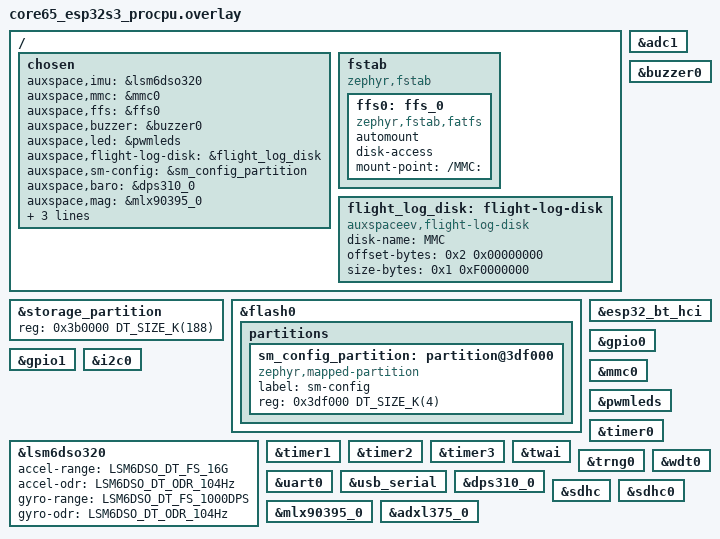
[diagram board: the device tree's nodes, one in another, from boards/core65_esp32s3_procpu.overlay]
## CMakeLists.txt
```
#-------------------------------------------------------------------------------
# Sensor Board prototype
#
# Copyright (c) 2025-2026 Auxspace e.V.
# SPDX-License-Identifier: Apache-2.0

cmake_minimum_required(VERSION 3.20.0)

# TODO: Exclude zephyr from SCA since it produces false positives
# set(ZEPHYR_SCA_VARIANT gcc)

# Make application-local snippets (e.g. ./snippets/sim) discoverable by
# `west build -S <name>` and twister's SNIPPET= extra_args.
list(APPEND SNIPPET_ROOT ${CMAKE_CURRENT_SOURCE_DIR})

find_package(Zephyr REQUIRED HINTS $ENV{ZEPHYR_BASE})

# The "app" library target below is created by find_package(Zephyr) (see
# zephyr/cmake/modules/kernel.cmake), independently of the project name.
project(sensor_board LANGUAGES C CXX)

target_sources(app PRIVATE
	src/main.c
	src/data.c
	)
```

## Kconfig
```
# Copyright (c) 2025-2026 Auxspace e.V.
# SPDX-License-Identifier: Apache-2.0
#
# This file is the application Kconfig entry point. All application Kconfig
# options can be defined here or included via other application Kconfig files.
# You can browse these options using the west targets menuconfig (terminal) or
# guiconfig (GUI).

menu "Zephyr"

source "Kconfig.zephyr"

endmenu

module = SENSOR_BOARD
module-str = SENSOR_BOARD
source "subsys/logging/Kconfig.template.log_config"

# The simulated sample sources themselves live with the sensors they stand
# in for; see AURORA_FAKE_SENSORS in aurora/lib/sensor/Kconfig.

config AURORA_SIM_AUTOTEST
	bool "Automated simulation test (CI mode)"
	depends on IMU && BARO
	depends on AURORA_STATE_MACHINE && SHELL
	select AURORA_FAKE_SENSORS
	select ASSERT
	help
	  Enables the full automated flight simulation for CI. Pulls in the
	  simulated sensors and assertion support, then has the state machine
	  thread launch the flight as soon as attitude calibration completes.
	  Exits with code 0 on SM_LANDED, code 1 on SM_ERROR or after
	  AURORA_SIM_AUTOLAUNCH_TIMEOUT_MS. Run ./zephyr.exe and check the
	  process exit code.

config AURORA_SIM_AUTOLAUNCH_TIMEOUT_MS
	int "Autolaunch watchdog timeout (ms)"
	depends on AURORA_SIM_AUTOTEST
	default 120000
	help
	  Maximum time in milliseconds to wait for SM_LANDED after launching
	  the flight. Exits with code 1 if this deadline is exceeded.

config SENSOR_BOARD_STATUS_INTERVAL_MS
	int "Telemetry status heartbeat interval (ms)"
	depends on AURORA_TELEMETRY && AURORA_STATE_MACHINE
	default 1000
	range 0 60000
	help
	  Period of the STATUS telemetry frame sent while the vehicle is
	  not in flight (pad, error hold, landed). It carries the flight
	  state and sensor/calibration/log health, and unlike SM updates
	  it does not wait for both sensors to report - so the ground
	  station hears from a board whose IMU or barometer is down.
	  Suppressed in flight, where it would compete with SM updates
	  for airtime. 0 disables it.

config SENSOR_BOARD_TELEMETRY_FOLLOW_SM
	bool "Send SM updates only when the state machine advances"
	depends on AURORA_TELEMETRY && AURORA_STATE_MACHINE
	default y
	help
	  When enabled, an SM_UPDATE frame goes out on every state machine
	  step, which only happens once both the IMU and the barometer have
	  delivered a sample.  Without a working barometer no SM_UPDATE is
	  ever sent; only the STATUS heartbeat reaches the ground.

	  When disabled, SM_UPDATE frames are sent from the flight loop
	  every SENSOR_BOARD_TELEMETRY_INTERVAL_MS, independent of the
	  state machine, carrying whatever the sensors last delivered.
	  Use this to keep the downlink alive when the state machine cannot
	  advance, e.g. flying without a barometer.  Altitude then stays 0;
	  acceleration, vertical acceleration and orientation come from the
	  IMU.  Backend rate limits (*_MIN_INTERVAL_MS) still apply.

config SENSOR_BOARD_TELEMETRY_INTERVAL_MS
	int "SM update interval when not following the state machine (ms)"
	depends on AURORA_TELEMETRY && AURORA_STATE_MACHINE
	depends on !SENSOR_BOARD_TELEMETRY_FOLLOW_SM
	default 100
	range 10 60000
	help
	  Period of the SM_UPDATE frames sent while
	  SENSOR_BOARD_TELEMETRY_FOLLOW_SM is disabled.
```

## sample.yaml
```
# Copyright (c) 2026 Auxspace e.V.
# SPDX-License-Identifier: Apache-2.0
#
# This file is provided so that the application can be compiled using Twister,
# the Zephyr testing tool. In this file, multiple combinations can be specified,
# so that you can easily test all of them locally or in CI.
sample:
  description: Sensor Board Application
  name: Sensor Board
common:
  build_only: true
  modules:
    - fatfs
tests:
  app.native_sim.replay:
    build_only: false
    timeout: 180
    harness: console
    harness_config:
      type: one_line
      regex:
        - "simulation complete"
    extra_overlay_confs:
      - boards/native_sim.conf
    extra_dtc_overlay_files:
      - boards/native_sim.overlay
    extra_configs:
      - CONFIG_AURORA_SIM_AUTOTEST=y
      - CONFIG_AURORA_FAKE_SENSORS_REPLAY=y
    platform_allow:
      - native_sim/native/64
    integration_platforms:
      - native_sim/native/64
  app.default.sysbuild:
    sysbuild: true
    platform_allow:
      - sensor_board_v2/rp2040
      - micrometer@2/esp32s3/procpu
      - core65@1/esp32s3/procpu
    integration_platforms:
      - sensor_board_v2/rp2040
      - micrometer@2/esp32s3/procpu
      - core65@1/esp32s3/procpu
  app.bench:
    extra_args: SNIPPET="sim;nodisk"
    platform_allow:
      - rpi_pico/rp2040/w
      - sensor_board_v2/rp2040
    integration_platforms:
      - rpi_pico/rp2040/w
      - sensor_board_v2/rp2040
  app.debug.sysbuild:
    sysbuild: true
    extra_overlay_confs:
      - debug.conf
    platform_allow:
      - sensor_board_v2/rp2040
      - micrometer@2/esp32s3/procpu
      - core65@1/esp32s3/procpu
    integration_platforms:
      - sensor_board_v2/rp2040
      - micrometer@2/esp32s3/procpu
      - core65@1/esp32s3/procpu
```

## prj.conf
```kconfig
# Copyright (c) 2026 Auxspace e.V.
# SPDX-License-Identifier: Apache-2.0
#
# common options, which apply to all boards (will be duplicated in board configs)

# Console and Shell
CONFIG_SHELL=y
CONFIG_SENSOR_SHELL=y

# Boot banner
CONFIG_BOOT_BANNER_STRING="Booting AURORA"

# Logging
CONFIG_LOG=y
CONFIG_LOG_FLUSH_SLEEP_US=1000
CONFIG_LOG_DEFAULT_LEVEL=3
CONFIG_LOG_TIMESTAMP_USE_REALTIME=y
CONFIG_LOG_SPEED=y
CONFIG_LOG_THREAD_ID_PREFIX=y
CONFIG_LOG_INFO_COLOR_GREEN=y
CONFIG_LOG_DBG_COLOR_BLUE=y
CONFIG_LOG_OUTPUT_FORMAT_TIME_TIMESTAMP=y
# CONFIG_LOG_BACKEND_FS_APPEND_TO_NEWEST_FILE is not set
# CONFIG_LOG_MEM_UTILIZATION is not set
CONFIG_LOG_CMDS=y
CONFIG_LOG_RATELIMIT_INTERVAL_MS=500

# State machine
CONFIG_AURORA_STATE_MACHINE=y
CONFIG_AURORA_STATE_MACHINE_SHELL=y

# The flight thread reads its samples directly; zbus is left for the observers
# that only listen in, such as the pad link.
CONFIG_ZBUS=y
CONFIG_ZBUS_CHANNEL_NAME=y

# Runtime healthchecks and supervision
CONFIG_STACK_SENTINEL=y
CONFIG_ASSERT=y
```

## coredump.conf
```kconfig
# Copyright (c) 2026 Auxspace e.V.
# SPDX-License-Identifier: Apache-2.0
#
# Post-mortem core dump persisted to the on-board "coredump" flash
# partition, then read back over the shell after the board comes up again:
#
#   uart:~$ coredump find     # is a dump stored, and is it valid?
#   uart:~$ coredump print    # emit the "#CD:" hex stream
#   uart:~$ coredump erase    # invalidate it before the next run
#
# Decode off-target against the matching ELF:
#   zephyr/scripts/coredump/coredump_serial_log_parse.py <captured> out.bin
#   zephyr/scripts/coredump/coredump_gdbserver.py build/zephyr/zephyr.elf out.bin
#
# Stack with the debug overlay for symbols + a text backtrace:
#   west build -b micrometer/esp32s3/procpu@2 aurora/sensor_board \
#       -- -DEXTRA_CONF_FILE="debug.conf;coredump.conf"
#
# Why flash and not BACKEND_LOGGING: on micrometer@2 the console is the
# ESP32-S3 USB-Serial-JTAG, whose poll_out (serial_esp32_usb.c) silently
# DISCARDS characters once the 64-byte TX FIFO stays full for 50 ms. A
# coredump is the largest burst the firmware ever emits and it is written
# in panic mode, so streaming it over that console loses most of it with no
# "dropped" marker. Flash survives the fault, the reboot, and a power
# cycle; the shell read-back afterwards is interrupt-driven and properly
# back-pressured, so it does not drop.

CONFIG_DEBUG_COREDUMP=y
CONFIG_DEBUG_COREDUMP_BACKEND_FLASH_PARTITION=y

# Read the stored dump back out on the next boot.
CONFIG_DEBUG_COREDUMP_SHELL=y

# Registers + the faulting thread's stack only: enough to reconstruct the
# backtrace of a NULL-deref crash. Switch to
CONFIG_DEBUG_COREDUMP_MEMORY_DUMP_THREADS=y
# if you need every thread's stack -- but see the size budget below first,
# it will not fit.
# CONFIG_DEBUG_COREDUMP_MEMORY_DUMP_MIN=y

# Size budget. The coredump partition inherited from
# espressif/partitions_0x0_amp_4M.dtsi is 4 KiB at 0x3ff000; the backend's
# 16-byte header (write-block-size is 4, so no erase-block padding) leaves
# 4080 bytes for data. The stack-top limits default to -1 == "dump to the
# end of the stack region", which for a 4 KiB thread stack overruns the
# partition and truncates the dump. Bound them so the whole thing fits:
#
#   coredump hdr ~12 + Xtensa arch block ~200 + k_thread ~350
#   + block headers ~30 + 2048 stack  ==  ~2.6 KiB of 4080.
#
# 2 KiB of stack top is generous on Xtensa, where register-window spills
# make frames large.
CONFIG_DEBUG_COREDUMP_THREAD_STACK_TOP=y
CONFIG_DEBUG_COREDUMP_THREAD_STACK_TOP_LIMIT_FOR_CURRENT=2048
CONFIG_DEBUG_COREDUMP_THREAD_STACK_TOP_LIMIT=1024

# Dump _kernel alongside the registers, so a decode can read the real
# cpus[0].current / .nested / .irq_stack instead of inferring them. Without
# this the scheduler-bookkeeping question cannot be settled from a dump.
CONFIG_DEBUG_COREDUMP_THREADS_METADATA=y
```

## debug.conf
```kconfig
# Copyright (c) 2021 Nordic Semiconductor ASA
# Copyright (c) 2026 Auxspace e.V.
# SPDX-License-Identifier: Apache-2.0
#
# This is a Kconfig fragment which can be used to enable debug-related options
# in the application. See the README for more details.

# kernel
CONFIG_DEBUG=y
CONFIG_DEBUG_THREAD_INFO=y

# Fatal-error handling.
#
# Zephyr's default with RESET_ON_FATAL_ERROR=n is arch_system_halt(): the
# board stops dead where it faulted. On micrometer@2 that is
# indistinguishable from a brownout or a flat pack, because the halt takes
# the console with it and the panic banner is lost in the USB-Serial-JTAG
# FIFO (see coredump.conf). Rebooting instead means the board comes back,
# re-prints the boot banner -- which is itself the proof that this was a
# fault and not a power loss -- and can be asked for the stored coredump.
#
# Debug-only on purpose: a flight build should not silently reboot a live
# state machine, so this stays out of prj.conf.
CONFIG_RESET_ON_FATAL_ERROR=y

# Reset-cause reporting. hwinfo_esp32 distinguishes POR / PIN / SOFTWARE /
# WATCHDOG / CPU_LOCKUP / BROWNOUT / LOW_POWER_WAKE, which is the one thing
# the console genuinely cannot tell you: whether the board panicked, was
# reset by the watchdog, browned out, or just lost power. main() logs and
# clears it at boot.
CONFIG_HWINFO=y

# Stack-overflow sanitisers
CONFIG_HW_STACK_PROTECTION=y
CONFIG_INIT_STACKS=y
CONFIG_THREAD_STACK_INFO=y
CONFIG_STACK_USAGE=y
CONFIG_EXCEPTION_STACK_TRACE=y

# compiler
CONFIG_SYMTAB=y
CONFIG_SYMTAB_SHELL=y
CONFIG_DEBUG_OPTIMIZATIONS=y
# Keep file:line (that is what names a panic) but drop the condition
# expression, which is the long half of every assert string. Assert strings
# land in DRAM rodata on esp32s3, and DRAM is the binding constraint here.
CONFIG_ASSERT_NO_COND_INFO=y

# healthchecks and supervision
CONFIG_AURORA_WATCHDOG_BREADCRUMB=y
CONFIG_ASSERT=y
CONFIG_ASSERT_LEVEL=2

# thread analyzing
CONFIG_THREAD_ANALYZER=y
CONFIG_THREAD_ANALYZER_AUTO=y
CONFIG_THREAD_ANALYZER_AUTO_STACK_SIZE=2048
CONFIG_THREAD_ANALYZER_USE_LOG=y
CONFIG_THREAD_NAME=y
CONFIG_ZBUS_CHANNEL_NAME=y

# logging
CONFIG_LOG=y

CONFIG_FS_LOG_LEVEL_DBG=y
CONFIG_PYRO_LOG_LEVEL_DBG=y
CONFIG_AURORA_SENSORS_LOG_LEVEL_DBG=y
CONFIG_AURORA_FILTER_LOG_LEVEL_DBG=y
CONFIG_DATA_LOGGER_LOG_LEVEL_DBG=y
CONFIG_STATE_MACHINE_LOG_LEVEL_DBG=y
CONFIG_AURORA_NOTIFY_LOG_LEVEL_DBG=y
CONFIG_AURORA_PWM_MELODY_LOG_LEVEL_DBG=y
CONFIG_AURORA_POWERFAIL_LOG_LEVEL_DBG=y
CONFIG_SENSOR_BOARD_LOG_LEVEL_DBG=y
CONFIG_AURORA_TELEMETRY_LOG_LEVEL_DBG=y
CONFIG_AURORA_PAD_LINK_LOG_LEVEL_DBG=y
CONFIG_AURORA_WATCHDOG_LOG_LEVEL_DBG=y

# powerfail
CONFIG_AURORA_POWERFAIL_SHUTDOWN=n

# Extra Shells for Debugging
CONFIG_ADC_SHELL=y
CONFIG_CAN_SHELL=y
CONFIG_GPIO_SHELL=y
CONFIG_I2C_SHELL=y
CONFIG_PWM_SHELL=y
CONFIG_PYRO_SHELL=y
CONFIG_WDT_SHELL=y
```

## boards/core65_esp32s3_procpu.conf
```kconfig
CONFIG_USE_DT_CODE_PARTITION=y
CONFIG_GPIO=y
CONFIG_AURORA_SENSORS=y
CONFIG_IMU=y
CONFIG_IMU_FREQUENCY=104
CONFIG_IMU_UP_AXIS_POS_Z=y
CONFIG_BARO=y
CONFIG_FILTER=y
CONFIG_FILTER_Q_VEL_MILLISCALE=3000
CONFIG_FILTER_R_MILLISCALE=6000
CONFIG_FILTER_APOGEE_DEBOUNCE_SAMPLES=3
CONFIG_ADC=y
CONFIG_CAN=y
CONFIG_UART_CONSOLE=y
CONFIG_PWM=y
CONFIG_LED=y
CONFIG_LED_PWM=y
CONFIG_SENSOR=y
CONFIG_LSM6DSO=y
CONFIG_LSM6DSO_TRIGGER_GLOBAL_THREAD=y
CONFIG_UART_LINE_CTRL=y
# CONFIG_UDC_DRIVER is not set
# CONFIG_UDC_DWC2 is not set
# CONFIG_USB_DEVICE_STACK is not set
# CONFIG_USB_DEVICE_STACK_NEXT is not set
# CONFIG_COMMON_LIBC_REMOVE is not set
CONFIG_FILE_SYSTEM=y
CONFIG_FILE_SYSTEM_SHELL=y
CONFIG_FILE_SYSTEM_SHELL_TEST_COMMANDS=y
CONFIG_FILE_SYSTEM_MKFS=y
CONFIG_FAT_FILESYSTEM_ELM=y
CONFIG_FS_FATFS_LFN=y
CONFIG_FS_FATFS_LFN_MODE_HEAP=y
CONFIG_FS_FATFS_REENTRANT=y
CONFIG_FS_FATFS_CUSTOM_MOUNT_POINT_COUNT=1
CONFIG_FS_FATFS_CUSTOM_MOUNT_POINTS="MMC"
CONFIG_LOG_BUFFER_SIZE=8192
CONFIG_LOG_BACKEND_FS=y
CONFIG_LOG_BACKEND_FS_DIR="/MMC:/LOGS"
CONFIG_LOG_BACKEND_FS_FILE_PREFIX="LOG."
CONFIG_LOG_BACKEND_FS_FILES_LIMIT=512
CONFIG_LOG_BACKEND_FS_FILE_SIZE=100000000
CONFIG_LOG_BACKEND_FS_AUTOSTART=y
CONFIG_LOG_BACKEND_UART=y
CONFIG_LOG_BACKEND_UART_BUFFER_SIZE=32
CONFIG_SHELL_LOG_BACKEND=n
CONFIG_DATA_LOGGER=y
CONFIG_DATA_LOGGER_DISK_AUTO_MKFS=n
CONFIG_DATA_LOGGER_BIN_BACKEND_FS=y
CONFIG_DATA_LOGGER_CONVERT_INFLUX=n
CONFIG_DATA_LOGGER_CONVERT_CSV=n
CONFIG_DATA_LOGGER_BASE_PATH="/MMC:/DATA"
CONFIG_DATA_LOGGER_SHELL=y
CONFIG_MMC_STACK=y
CONFIG_AURORA_NOTIFY=y
CONFIG_AURORA_NOTIFY_BUZZER=y
CONFIG_AURORA_NOTIFY_LED=y
CONFIG_AURORA_WATCHDOG=y
CONFIG_AURORA_STATE_MACHINE_AUDIT=y
CONFIG_AURORA_STATE_MACHINE_AUDIT_BASE_PATH="/MMC:/STATE"
CONFIG_AURORA_STATE_MACHINE_RBF=y
CONFIG_AURORA_STATE_MACHINE_RETAIN=y

# Pad Link
CONFIG_AURORA_PAD_LINK=y
CONFIG_BT_L2CAP_TX_MTU=247
CONFIG_BT_BUF_ACL_RX_SIZE=251
CONFIG_BT_BUF_ACL_TX_SIZE=251
CONFIG_COMMON_LIBC_MALLOC_ARENA_SIZE=16384
CONFIG_HEAP_MEM_POOL_SIZE=32768

# Flight of about 50-60 m height with a 6N Motor

# Metrics
CONFIG_BOOST_ACCELERATION=15
CONFIG_BOOST_ALTITUDE=5
CONFIG_BURNOUT_ACCELERATION=10
CONFIG_MAIN_DESCENT_HEIGHT=25
CONFIG_LANDING_VELOCITY=2

# Timers
CONFIG_BOOST_TIMER_MS=200

# Timeouts
CONFIG_APOGEE_TIMEOUT_MS=20000
CONFIG_MAIN_TIMEOUT_MS=2000

# I2C
CONFIG_I2C=y

# Flight thresholds persist in the sm-config flash page (see micrometer_v2.dtsi).
CONFIG_FLASH=y
CONFIG_AURORA_STATE_MACHINE_CONFIG_STORE=y

# Every bmp581 register access goes through the RTIO work queue, so the baro
# poller alone keeps items in flight continuously.
CONFIG_RTIO_WORKQ_POOL_ITEMS=2

# Disk
CONFIG_AURORA_NOTIFY_DISK_LED=y

# Stacks
CONFIG_IDLE_STACK_SIZE=2048
CONFIG_ISR_STACK_SIZE=4096
CONFIG_BT_TX_PROCESSOR_STACK_SIZE=2048
CONFIG_RTIO_WORKQ_THREADS_POOL_STACK_SIZE=4096
CONFIG_LOG_PROCESS_THREAD_STACK_SIZE=4096
CONFIG_SHELL_STACK_SIZE=4096
CONFIG_SYSTEM_WORKQUEUE_STACK_SIZE=4096
CONFIG_DATA_LOGGER_BIN_WRITER_STACK_SIZE=4096
CONFIG_DATA_LOGGER_LOGGER_STACK_SIZE=4096
CONFIG_DATA_LOGGER_CONVERTER_STACK_SIZE=4096
```

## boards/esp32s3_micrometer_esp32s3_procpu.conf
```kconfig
CONFIG_USE_DT_CODE_PARTITION=y
CONFIG_GPIO=y
CONFIG_LOG_PROCESS_THREAD_STACK_SIZE=4096
CONFIG_PYRO=y
CONFIG_PYRO_SHELL=y
CONFIG_AURORA_SENSORS=y
CONFIG_IMU=y
CONFIG_IMU_UP_AXIS_POS_Y=y
CONFIG_BARO=y
CONFIG_FILTER=y
CONFIG_FILTER_Q_VEL_MILLISCALE=3000
CONFIG_FILTER_R_MILLISCALE=6000
CONFIG_FILTER_APOGEE_DEBOUNCE_SAMPLES=3
CONFIG_ADC=y
CONFIG_ADC_SHELL=y
CONFIG_CAN=y
CONFIG_CAN_SHELL=y
CONFIG_UART_CONSOLE=y
CONFIG_SHELL_STACK_SIZE=4096
CONFIG_SYSTEM_WORKQUEUE_STACK_SIZE=4096
CONFIG_PWM=y
CONFIG_PWM_SHELL=y
CONFIG_LED=y
CONFIG_LED_PWM=y
CONFIG_SENSOR=y
CONFIG_LSM6DSO=y
CONFIG_LSM6DSO_TRIGGER_OWN_THREAD=y
CONFIG_LSM6DSO_THREAD_STACK_SIZE=1024
CONFIG_LSM6DSO_THREAD_PRIORITY=3
CONFIG_LSM6DSO_ENABLE_TEMP=y
CONFIG_LPS22HH=y
CONFIG_LPS22HH_TRIGGER_OWN_THREAD=y
CONFIG_LPS22HH_THREAD_STACK_SIZE=1024
CONFIG_LPS22HH_THREAD_PRIORITY=4
CONFIG_UART_LINE_CTRL=y
# CONFIG_UDC_DRIVER is not set
# CONFIG_UDC_DWC2 is not set
# CONFIG_USB_DEVICE_STACK is not set
# CONFIG_USB_DEVICE_STACK_NEXT is not set
# CONFIG_COMMON_LIBC_REMOVE is not set
CONFIG_FILE_SYSTEM=y
CONFIG_FILE_SYSTEM_SHELL=y
CONFIG_FILE_SYSTEM_SHELL_TEST_COMMANDS=y
CONFIG_FILE_SYSTEM_MKFS=y
CONFIG_FAT_FILESYSTEM_ELM=y
CONFIG_FS_FATFS_EXFAT=y
CONFIG_FS_FATFS_LBA64=y
CONFIG_FS_FATFS_CUSTOM_MOUNT_POINT_COUNT=1
CONFIG_FS_FATFS_CUSTOM_MOUNT_POINTS="MMC"
CONFIG_LOG_BACKEND_FS=y
CONFIG_LOG_BACKEND_FS_DIR="/MMC:/logs"
CONFIG_LOG_BACKEND_FS_FILES_LIMIT=512
CONFIG_LOG_BACKEND_FS_FILE_SIZE=100000000
CONFIG_LOG_BACKEND_UART=y
CONFIG_LOG_BACKEND_UART_BUFFER_SIZE=32
CONFIG_SHELL_LOG_BACKEND=n
CONFIG_DATA_LOGGER=y
CONFIG_DATA_LOGGER_CONVERT_INFLUX=y
CONFIG_DATA_LOGGER_BASE_PATH="/MMC:/data"
CONFIG_DATA_LOGGER_SHELL=y
CONFIG_DATA_LOGGER_BIN=y
CONFIG_MMC_STACK=y
CONFIG_AURORA_NOTIFY=y
CONFIG_AURORA_NOTIFY_BUZZER=y
CONFIG_AURORA_NOTIFY_LED=y
CONFIG_AURORA_STATE_MACHINE_AUDIT=y
CONFIG_AURORA_STATE_MACHINE_AUDIT_BASE_PATH="/MMC:/state"
CONFIG_AURORA_POWERFAIL=y

# Flight of about 50-60 m height with a 6N Motor

# Metrics
CONFIG_BOOST_ACCELERATION=15
CONFIG_BOOST_ALTITUDE=5
CONFIG_BURNOUT_ACCELERATION=10
CONFIG_MAIN_DESCENT_HEIGHT=25
CONFIG_LANDING_VELOCITY=2

# Timers
CONFIG_BOOST_TIMER_MS=200

# Timeouts
CONFIG_APOGEE_TIMEOUT_MS=20000
CONFIG_MAIN_TIMEOUT_MS=2000
```

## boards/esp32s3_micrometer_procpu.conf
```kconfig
CONFIG_USE_DT_CODE_PARTITION=y
CONFIG_GPIO=y
CONFIG_LOG=y
CONFIG_LOG_PROCESS_THREAD_STACK_SIZE=1024
CONFIG_CONSOLE=y
CONFIG_AURORA_STATE_MACHINE=y
CONFIG_BOOT_BANNER_STRING="Booting AURORA"
CONFIG_HEAP_MEM_POOL_SIZE=16384
CONFIG_UART_CONSOLE=y
CONFIG_SENSOR=y
CONFIG_SENSOR_SHELL=y
# CONFIG_COMMON_LIBC_REMOVE is not set
CONFIG_FILE_SYSTEM=y
CONFIG_FILE_SYSTEM_SHELL=y
CONFIG_FILE_SYSTEM_SHELL_TEST_COMMANDS=y
CONFIG_FILE_SYSTEM_MKFS=y
CONFIG_FAT_FILESYSTEM_ELM=y
CONFIG_LOG_DEFAULT_LEVEL=2
CONFIG_LOG_TIMESTAMP_USE_REALTIME=y
CONFIG_LOG_SPEED=y
CONFIG_LOG_THREAD_ID_PREFIX=y
CONFIG_LOG_OUTPUT_FORMAT_TIME_TIMESTAMP=y
CONFIG_LOG_BACKEND_FS=y
CONFIG_LOG_BACKEND_FS_DIR="MMC:/logs"
CONFIG_LOG_BACKEND_UART=y
CONFIG_LOG_CMDS=y
CONFIG_SHELL=y
CONFIG_USBD_CDC_ACM_LOG_LEVEL_OFF=y
CONFIG_CDC_ACM_SERIAL_INITIALIZE_AT_BOOT=y
CONFIG_USB_CONSOLE_SHELL=y
```

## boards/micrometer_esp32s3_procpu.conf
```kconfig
CONFIG_USE_DT_CODE_PARTITION=y
CONFIG_GPIO=y
CONFIG_PYRO=y
CONFIG_AURORA_SENSORS=y
CONFIG_IMU=y
CONFIG_IMU_FREQUENCY=104
CONFIG_IMU_UP_AXIS_POS_Y=y
CONFIG_BARO=y
CONFIG_FILTER=y
CONFIG_FILTER_Q_VEL_MILLISCALE=3000
CONFIG_FILTER_R_MILLISCALE=6000
CONFIG_FILTER_APOGEE_DEBOUNCE_SAMPLES=3
CONFIG_ADC=y
CONFIG_CAN=y
CONFIG_UART_CONSOLE=y
CONFIG_PWM=y
CONFIG_LED=y
CONFIG_LED_PWM=y
CONFIG_SENSOR=y
CONFIG_LSM6DSO=y
CONFIG_LSM6DSO_TRIGGER_GLOBAL_THREAD=y
# Barometer differs per board revision; its driver Kconfig lives in the
# revision-specific configs (micrometer_esp32s3_procpu_{1,2}.conf).
CONFIG_UART_LINE_CTRL=y
# CONFIG_UDC_DRIVER is not set
# CONFIG_UDC_DWC2 is not set
# CONFIG_USB_DEVICE_STACK is not set
# CONFIG_USB_DEVICE_STACK_NEXT is not set
# CONFIG_COMMON_LIBC_REMOVE is not set
CONFIG_FILE_SYSTEM=y
CONFIG_FILE_SYSTEM_SHELL=y
CONFIG_FILE_SYSTEM_SHELL_TEST_COMMANDS=y
CONFIG_FILE_SYSTEM_MKFS=y
CONFIG_FAT_FILESYSTEM_ELM=y
CONFIG_FS_FATFS_LFN=y
CONFIG_FS_FATFS_LFN_MODE_HEAP=y
CONFIG_FS_FATFS_REENTRANT=y
CONFIG_FS_FATFS_CUSTOM_MOUNT_POINT_COUNT=1
CONFIG_FS_FATFS_CUSTOM_MOUNT_POINTS="MMC"
CONFIG_LOG_BUFFER_SIZE=8192
CONFIG_LOG_BACKEND_FS=y
CONFIG_LOG_BACKEND_FS_DIR="/MMC:/LOGS"
CONFIG_LOG_BACKEND_FS_FILE_PREFIX="LOG."
CONFIG_LOG_BACKEND_FS_FILES_LIMIT=512
CONFIG_LOG_BACKEND_FS_FILE_SIZE=100000000
CONFIG_LOG_BACKEND_FS_AUTOSTART=y
CONFIG_LOG_BACKEND_UART=y
CONFIG_LOG_BACKEND_UART_BUFFER_SIZE=32
CONFIG_SHELL_LOG_BACKEND=n
CONFIG_DATA_LOGGER=y
CONFIG_DATA_LOGGER_DISK_AUTO_MKFS=n
CONFIG_DATA_LOGGER_BIN_BACKEND_FS=y
CONFIG_DATA_LOGGER_CONVERT_INFLUX=n
CONFIG_DATA_LOGGER_CONVERT_CSV=n
CONFIG_DATA_LOGGER_BASE_PATH="/MMC:/DATA"
CONFIG_DATA_LOGGER_SHELL=y
CONFIG_MMC_STACK=y
CONFIG_AURORA_NOTIFY=y
CONFIG_AURORA_NOTIFY_BUZZER=y
CONFIG_AURORA_NOTIFY_LED=y
CONFIG_AURORA_WATCHDOG=y
CONFIG_AURORA_STATE_MACHINE_AUDIT=y
CONFIG_AURORA_STATE_MACHINE_AUDIT_BASE_PATH="/MMC:/STATE"
CONFIG_AURORA_STATE_MACHINE_RBF=y
CONFIG_AURORA_STATE_MACHINE_RETAIN=y

# Pad Link
CONFIG_AURORA_PAD_LINK=y
CONFIG_BT_L2CAP_TX_MTU=247
CONFIG_BT_BUF_ACL_RX_SIZE=251
CONFIG_BT_BUF_ACL_TX_SIZE=251
CONFIG_COMMON_LIBC_MALLOC_ARENA_SIZE=16384
CONFIG_HEAP_MEM_POOL_SIZE=32768

# Flight of about 50-60 m height with a 6N Motor

# Metrics
CONFIG_BOOST_ACCELERATION=15
CONFIG_BOOST_ALTITUDE=5
CONFIG_BURNOUT_ACCELERATION=10
CONFIG_MAIN_DESCENT_HEIGHT=25
CONFIG_LANDING_VELOCITY=2

# Timers
CONFIG_BOOST_TIMER_MS=200

# Timeouts
CONFIG_APOGEE_TIMEOUT_MS=20000
CONFIG_MAIN_TIMEOUT_MS=2000

# I2C
CONFIG_I2C=y

# Flight thresholds persist in the sm-config flash page (see micrometer_v2.dtsi).
CONFIG_FLASH=y
CONFIG_AURORA_STATE_MACHINE_CONFIG_STORE=y

# Every bmp581 register access goes through the RTIO work queue, so the baro
# poller alone keeps items in flight continuously.
CONFIG_RTIO_WORKQ_POOL_ITEMS=2

# Stacks
CONFIG_IDLE_STACK_SIZE=2048
CONFIG_ISR_STACK_SIZE=4096
CONFIG_BT_TX_PROCESSOR_STACK_SIZE=2048
CONFIG_RTIO_WORKQ_THREADS_POOL_STACK_SIZE=4096
CONFIG_LOG_PROCESS_THREAD_STACK_SIZE=4096
CONFIG_SHELL_STACK_SIZE=4096
CONFIG_SYSTEM_WORKQUEUE_STACK_SIZE=4096
CONFIG_DATA_LOGGER_BIN_WRITER_STACK_SIZE=4096
CONFIG_DATA_LOGGER_LOGGER_STACK_SIZE=4096
CONFIG_DATA_LOGGER_CONVERTER_STACK_SIZE=4096

# CAN
CONFIG_CAN=y
CONFIG_SHELL=y
CONFIG_CAN_SHELL=y
CONFIG_STATS=y
CONFIG_CAN_STATS=y
```

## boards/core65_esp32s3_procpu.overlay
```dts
/*
 * Copyright (c) 2026 Auxspace e.V.
 * SPDX-License-Identifier: Apache-2.0
 */

#include <zephyr/dt-bindings/sensor/lps22hh.h>
#include <zephyr/dt-bindings/sensor/lsm6dso.h>

/ {
	chosen {
		/* Auxspace specific */
		auxspace,imu = &lsm6dso320;
		auxspace,mmc = &mmc0;
		auxspace,ffs = &ffs0;
		auxspace,buzzer = &buzzer0;
		auxspace,led = &pwmleds;
		auxspace,flight-log-disk = &flight_log_disk;
		auxspace,sm-config = &sm_config_partition;
		auxspace,baro = &dps310_0;
		auxspace,mag = &mlx90395_0;
		auxspace,haccel = &adxl375_0;
		auxspace,disk-led = &sd_activity_led;
		/* no dedicated RBF connector.
		 * The BOOT button stands in for the plug (shorted = safe).
		 */
		auxspace,rbf = &button0;
	};

	fstab {
		compatible = "zephyr,fstab";

		ffs0: ffs_0 {
			compatible = "zephyr,fstab,fatfs";
			automount;
			disk-access;
			mount-point = "/MMC:";
		};
	};

	flight_log_disk: flight-log-disk {
		compatible = "auxspaceev,flight-log-disk";
		disk-name = "MMC";
		offset-bytes = <0x2 0x00000000>;	/* 8 GiB */
		size-bytes   = <0x1 0xF0000000>;	/* 7 GiB and 512 MiB */
	};
};

/* The 4M layout inherited from partitions_0x0_amp_4M.dtsi leaves no gap, so
 * the flight-threshold page comes out of the tail of the unused storage
 * partition: 192K => 188K.
 */
&storage_partition {
	reg = <0x3b0000 DT_SIZE_K(188)>;
};

&flash0 {
	partitions {
		/* One erase page (4K); the state machine erases and rewrites
		 * the whole thing on every save.
		 */
		sm_config_partition: partition@3df000 {
			compatible = "zephyr,mapped-partition";
			label = "sm-config";
			reg = <0x3df000 DT_SIZE_K(4)>;
		};
	};
};

&adc1 {
	status = "okay";
};

&buzzer0 {
	status = "okay";
};

&esp32_bt_hci {
	status = "okay";
};

&gpio0 {
	status = "okay";
};

&gpio1 {
	status = "okay";
};

&i2c0 {
	status = "okay";
};

&lsm6dso320 {
	status = "okay";
	accel-range = <LSM6DSO_DT_FS_16G>;
	accel-odr = <LSM6DSO_DT_ODR_104Hz>;
	gyro-range = <LSM6DSO_DT_FS_1000DPS>;
	gyro-odr = <LSM6DSO_DT_ODR_104Hz>;
};

&mmc0 {
	status = "okay";
};

&pwmleds {
	status = "okay";
};


&timer0 {
	status = "okay";
};

&timer1 {
	status = "okay";
};

&timer2 {
	status = "okay";
};

&timer3 {
	status = "okay";
};

&twai {
	status = "okay";
};

&trng0 {
	status = "okay";
};

&uart0 {
	status = "okay";
};

&usb_serial {
	status = "okay";
};

&wdt0 {
	status = "okay";
};

&dps310_0 {
	status = "okay";
};

&sdhc {
	status = "okay";
};

&sdhc0 {
	status = "okay";
};

&mlx90395_0 {
	status = "okay";
};

&adxl375_0 {
	status = "okay";
};
```

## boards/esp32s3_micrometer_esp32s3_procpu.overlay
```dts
/*
 * Copyright (c) 2026 Auxspace e.V.
 * SPDX-License-Identifier: Apache-2.0
 */

#include <zephyr/dt-bindings/sensor/lps22hh.h>
#include <zephyr/dt-bindings/sensor/lsm6dso.h>

/ {
	chosen {
		/* Auxspace specific */
		auxspace,baro = &lps22hh0;
		auxspace,imu = &lsm6dso320;
		auxspace,mmc = &mmc0;
		auxspace,pyro = &pyro0;
		auxspace,ffs = &ffs0;
		auxspace,buzzer = &buzzer0;
		auxspace,led = &pwmleds;
		auxspace,pfm = &button0;
		auxspace,flight-log-disk = &flight_log_disk;
	};

	fstab {
		compatible = "zephyr,fstab";

		ffs0: ffs_0 {
			compatible = "zephyr,fstab,fatfs";
			automount;
			disk-access;
			mount-point = "/MMC:";
		};
	};

	flight_log_disk: flight-log-disk {
		compatible = "auxspaceev,flight-log-disk";
		disk-name = "MMC";
		offset-sectors = <2097152>;
		size-sectors   = <524288>;
	};
};


&adc1 {
	status = "okay";
};

&buzzer0 {
	status = "okay";
};

&gpio0 {
	status = "okay";
};

&gpio1 {
	status = "okay";
};

&i2c0 {
	status = "okay";
};

&lps22hh0 {
	status = "okay";
	odr = <LPS22HH_DT_ODR_100HZ>;
};

&lsm6dso320 {
	status = "okay";
	accel-range = <LSM6DSO_DT_FS_16G>;
	accel-odr = <LSM6DSO_DT_ODR_104Hz>;
	gyro-range = <LSM6DSO_DT_FS_1000DPS>;
	gyro-odr = <LSM6DSO_DT_ODR_104Hz>;
};

&mmc0 {
	status = "okay";
};

&pwmleds {
	status = "okay";
};

&pyro0 {
	status = "okay";
};

&sdhc2 {
	status = "okay";
};

&spi2 {
	status = "okay";
};

&timer0 {
	status = "okay";
};

&timer1 {
	status = "okay";
};

&timer2 {
	status = "okay";
};

&timer3 {
	status = "okay";
};

&twai {
	status = "okay";
};

&trng0 {
	status = "okay";
};

&uart0 {
	status = "okay";
};

&usb_serial {
	status = "okay";
};

&wdt0 {
	status = "okay";
};
```

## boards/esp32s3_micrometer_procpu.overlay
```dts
/*
 * Copyright (c) 2026 Auxspace e.V.
 * SPDX-License-Identifier: Apache-2.0
 */

/ {
	chosen {
		auxspace,ffs = &ffs0;
	};

	fstab {
		compatible = "zephyr,fstab";

		ffs0: ffs_0 {
			compatible = "zephyr,fstab,fatfs";
			automount;
			disk-access;
			mount-point = "/MMC:";
		};
	};
};

&usb_serial {
	status = "okay";
};

&sdhc2 {
	status = "okay";
};

&mmc0 {
	status = "okay";
};

&spi2 {
	status = "okay";
};

&spi3 {
	status = "okay";
};

&i2c0 {
	status = "okay";
};

&i2c1 {
	status = "okay";
};

&lps22hh0 {
	status = "okay";
};

&lsm6dso320 {
	status = "okay";
};
```

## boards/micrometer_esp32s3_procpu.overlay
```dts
/*
 * Copyright (c) 2026 Auxspace e.V.
 * SPDX-License-Identifier: Apache-2.0
 */

#include <zephyr/dt-bindings/sensor/lps22hh.h>
#include <zephyr/dt-bindings/sensor/lsm6dso.h>

/ {
	chosen {
		/* Auxspace specific */
		auxspace,imu = &lsm6dso320;
		auxspace,mmc = &mmc0;
		auxspace,pyro = &pyro0;
		auxspace,ffs = &ffs0;
		auxspace,buzzer = &buzzer0;
		auxspace,led = &pwmleds;
		auxspace,flight-log-disk = &flight_log_disk;
		auxspace,sm-config = &sm_config_partition;
	};

	fstab {
		compatible = "zephyr,fstab";

		ffs0: ffs_0 {
			compatible = "zephyr,fstab,fatfs";
			automount;
			disk-access;
			mount-point = "/MMC:";
		};
	};

	flight_log_disk: flight-log-disk {
		compatible = "auxspaceev,flight-log-disk";
		disk-name = "MMC";
		offset-bytes = <0x2 0x00000000>;	/* 8 GiB */
		size-bytes   = <0x1 0xF0000000>;	/* 7 GiB and 512 MiB */
	};
};

/* The 4M layout inherited from partitions_0x0_amp_4M.dtsi leaves no gap, so
 * the flight-threshold page comes out of the tail of the unused storage
 * partition: 192K => 188K.
 */
&storage_partition {
	reg = <0x3b0000 DT_SIZE_K(188)>;
};

&flash0 {
	partitions {
		/* One erase page (4K); the state machine erases and rewrites
		 * the whole thing on every save.
		 */
		sm_config_partition: partition@3df000 {
			compatible = "zephyr,mapped-partition";
			label = "sm-config";
			reg = <0x3df000 DT_SIZE_K(4)>;
		};
	};
};

&adc1 {
	status = "okay";
};

&buzzer0 {
	status = "okay";
};

&esp32_bt_hci {
	status = "okay";
};

&gpio0 {
	status = "okay";
};

&gpio1 {
	status = "okay";
};

&i2c0 {
	status = "okay";
};

&lsm6dso320 {
	status = "okay";
	accel-range = <LSM6DSO_DT_FS_16G>;
	accel-odr = <LSM6DSO_DT_ODR_104Hz>;
	gyro-range = <LSM6DSO_DT_FS_1000DPS>;
	gyro-odr = <LSM6DSO_DT_ODR_104Hz>;
};

&mmc0 {
	status = "okay";
};

&pwmleds {
	status = "okay";
};

&pyro0 {
	status = "okay";
};

&timer0 {
	status = "okay";
};

&timer1 {
	status = "okay";
};

&timer2 {
	status = "okay";
};

&timer3 {
	status = "okay";
};

&twai {
	status = "okay";
};

&trng0 {
	status = "okay";
};

&uart0 {
	status = "okay";
};

&usb_serial {
	status = "okay";
};

&wdt0 {
	status = "okay";
};
```

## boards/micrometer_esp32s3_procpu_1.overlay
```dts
/*
 * Copyright (c) 2025-2026 Auxspace e.V.
 * SPDX-License-Identifier: Apache-2.0
 *
 * µMETER rev.1: Rocinante
 */

/ {
	chosen {
		/* Auxspace specific */
		auxspace,baro = &lps22hh0;
		/* no dedicated RBF connector.
		 * The BOOT button stands in for the plug (shorted = safe).
		 */
		auxspace,rbf = &button0;
	};
};

&lps22hh0 {
	status = "okay";
	odr = <LPS22HH_DT_ODR_50HZ>;
};

&spi2 {
	status = "okay";
};

&sdhc2 {
	status = "okay";
};
```

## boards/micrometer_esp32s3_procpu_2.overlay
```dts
/*
 * Copyright (c) 2025-2026 Auxspace e.V.
 * SPDX-License-Identifier: Apache-2.0
 *
 * µMETER rev.2: Razorback
 */

/ {
	chosen {
		/* Auxspace specific */
		auxspace,baro = &bmp581_0;
		auxspace,rbf = &button1;
		auxspace,vbat = &vbatt;
		auxspace,disk-led = &sd_activity_led;
		auxspace,telemetry-hc12 = &hc12;
	};

	hc12: hc12 {
		compatible = "auxspaceev,hc12";
		uart = <&uart0>;
		status = "okay";
	};
};

&bmp581_0 {
	status = "okay";
	odr = <BMP581_DT_ODR_100_2_HZ>;
};

&vbatt {
	status = "okay";
};

&sdhc {
	status = "okay";
};

&sdhc0 {
	status = "okay";
};
```

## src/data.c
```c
/**
 * @file data.c
 * @brief Flight-time logging lifecycle and telemetry glue for the sensor board.
 *
 * Drives the binary data logger across flight state transitions and enqueues
 * state-machine telemetry datapoints.
 *
 * Copyright (c) 2025-2026 Auxspace e.V.
 * SPDX-License-Identifier: Apache-2.0
 */

#include "data.h"
#include <stdint.h>
#include <stdio.h>
#include <zephyr/device.h>
#include <zephyr/drivers/sensor.h>
#include <zephyr/fs/fs.h>
#include <zephyr/logging/log.h>
#include <aurora/lib/baro.h>
#include <aurora/lib/data_logger.h>
#include <aurora/lib/notify.h>
#include <aurora/lib/state/state.h>

#if defined(CONFIG_AURORA_PAD_LINK)
#include <aurora/lib/pad_link.h>
#endif /* CONFIG_AURORA_PAD_LINK */

#if defined(CONFIG_DATA_LOGGER_BIN)
LOG_MODULE_DECLARE(main, CONFIG_SENSOR_BOARD_LOG_LEVEL);

K_THREAD_DEFINE(logger_thread, CONFIG_DATA_LOGGER_LOGGER_STACK_SIZE, logger_task, NULL, NULL, NULL,
		8, 0, 0);
#if defined(CONFIG_DATA_LOGGER_CONVERT)
K_THREAD_DEFINE(converter_thread, CONFIG_DATA_LOGGER_CONVERTER_STACK_SIZE, converter_task, NULL,
		NULL, NULL, 9, 0, 0);
#endif /* CONFIG_DATA_LOGGER_CONVERT */

/* Latched (until reboot) when opening the flight log at ARM time fails.
 * Feeds log_flight_log_online() so the state machine drops back from ARMED
 * to IDLE instead of sitting armed without a recording.  Deliberately never
 * cleared: clearing it on disarm would let the unchanged inputs re-arm
 * immediately and oscillate the pyro channels.
 */
static atomic_t flight_recording_failed = ATOMIC_INIT(0);

static void log_begin_flight(void)
{
#if defined(CONFIG_DATA_LOGGER_CONVERT)
	/* Only meaningful when a converter can own the recorder after landing.
	 * Without one there is nothing to wait for.
	 */
	if (k_sem_take(&convert_idle, K_MSEC(LOG_ARM_CONVERT_TIMEOUT_MS)) != 0) {
		LOG_ERR("ARMED: prior conversion still running after %d ms — "
				"flight will not be logged",
			LOG_ARM_CONVERT_TIMEOUT_MS);
		atomic_set(&flight_recording_failed, 1);
#if defined(CONFIG_AURORA_NOTIFY)
		notify_error();
#endif
		return;
	}
	k_sem_give(&convert_idle);
#endif /* CONFIG_DATA_LOGGER_CONVERT */

	/* Deliberately no memset of sm_logger here since its state carries the
	 * mutex that serialises logger_task against data_logger_close().
	 */
	if (data_logger_init(&sm_logger, "flight", &data_logger_bin_formatter) != 0) {
		LOG_ERR("data_logger_init failed");
		atomic_set(&flight_recording_failed, 1);
#if defined(CONFIG_AURORA_NOTIFY)
		notify_error();
#endif
		return;
	}
	data_logger_set_default(&sm_logger);
	if (data_logger_start(&sm_logger) != 0) {
		LOG_ERR("data_logger_start failed");
		atomic_set(&flight_recording_failed, 1);
		(void)data_logger_close(&sm_logger);
		data_logger_set_default(NULL);
#if defined(CONFIG_AURORA_NOTIFY)
		notify_error();
#endif
		return;
	}

	atomic_set(&sm_logger_live, 1);
}

static void log_end_flight(void)
{
	if (!atomic_get(&sm_logger_live)) {
		return;
	}
	atomic_set(&sm_logger_live, 0);

	(void)data_logger_stop(&sm_logger);
	(void)data_logger_close(&sm_logger);
	data_logger_set_default(NULL);
	data_logger_convert_request();
}

/* Delayable close: scheduled by the state-machine task on entry to
 * LANDED so the post-landed pad window gets logged before the logger is
 * closed and conversion kicks in.
 */
static void log_end_work_handler(struct k_work *work)
{
	ARG_UNUSED(work);
	log_end_flight();
}
static K_WORK_DELAYABLE_DEFINE(log_end_work, log_end_work_handler);
bool log_flight_log_online(void)
{
	/* An ARM-time open failure outranks the boot latch: the disk looked
	 * fine at boot but the recorder could not be opened when it mattered.
	 */
	if (atomic_get(&flight_recording_failed)) {
		return false;
	}
#if defined(CONFIG_DATA_LOGGER_DISK_AUTO_MKFS)
	return flight_log_online();
#else
	/* No disk bring-up module.  Nothing to gate on at boot. */
	return true;
#endif
}

bool log_flight_log_busy(void)
{
	return data_logger_convert_busy();
}

void log_begin_session(void)
{
	if (IS_ENABLED(CONFIG_DATA_LOGGER_LOG_ONLY_INFLIGHT)) {
		return;
	}

	LOG_INF("Data logger: recording continuously (LOG_ONLY_INFLIGHT=n)");
	log_begin_flight();
}

void log_handle_flight_lifecycle(const enum sm_state prev_state, const enum sm_state state)
{
	if (!IS_ENABLED(CONFIG_DATA_LOGGER_LOG_ONLY_INFLIGHT)) {
		/* The log was opened at boot by log_begin_session() and stays
		 * open for the whole power cycle; transitions only annotate it.
		 */
		if (prev_state == SM_ARMED && state == SM_BOOST) {
			(void)data_logger_event(&sm_logger, DLE_BOOST);
		} else if (state == SM_LANDED) {
			(void)data_logger_event(&sm_logger, DLE_LANDED);
		}
		return;
	}


	/* Flight-time logging lifecycle:
	 *  - IDLE→ARMED:  open the binary log (cancel any
	 *                 still-pending deferred close from a
	 *                 previous flight first). The FS backend
	 *                 keeps one file per boot session, so a
	 *                 re-arm appends rather than rotating.
	 *                 Calibration itself
	 *                 runs continuously while IDLE, potentially
	 *                 well before this arm edge, so it is
	 *                 deliberately not captured -- only the
	 *                 bounded flight-adjacent window from arming
	 *                 onward is.
	 *  - ARMED→BOOST: hand the formatter a BOOST event so
	 *                 the circular ring freezes forward.
	 *  - →LANDED:     hand a LANDED event and schedule the
	 *                 close POST_LANDED_PAD_MS later so the
	 *                 tail of the flight gets captured.
	 *  - →IDLE/ERROR: close immediately (no pad); cancel
	 *                 any pending deferred close.
	 */
	if (prev_state == SM_IDLE && state == SM_ARMED) {
		(void)k_work_cancel_delayable(&log_end_work);
		log_begin_flight();
	} else if (prev_state == SM_ARMED && state == SM_BOOST) {
		(void)data_logger_event(&sm_logger, DLE_BOOST);
	} else if (state == SM_LANDED) {
		(void)data_logger_event(&sm_logger, DLE_LANDED);
		(void)k_work_schedule(&log_end_work, K_MSEC(CONFIG_DATA_LOGGER_BIN_POST_LANDED_PAD_MS));
	} else if (state == SM_IDLE || state == SM_ERROR) {
		(void)k_work_cancel_delayable(&log_end_work);
		log_end_flight();
	}
}

/* log_resume_flight_after_reset - see data.h */
void log_resume_flight_after_reset(const enum sm_state state)
{
	/* The reset closed the previous log the hard way, so there is nothing
	 * open, nothing to cancel, and no deferred close pending.  The
	 * remainder of the flight lands in a fresh file; the pre-reset part is
	 * whatever the ring had already committed to the previous one.
	 *
	 * Only the airborne states open a log.  LANDED is deliberately left
	 * alone: the flight is over, so a log opened here would only ever
	 * contain the pad, and it is the case that made
	 * log_handle_flight_lifecycle() unsafe to replay wholesale -- its
	 * LANDED branch schedules a close for a log that was never opened.
	 * IDLE and ERROR have nothing to record either.
	 */
	if (state == SM_IDLE || state == SM_ERROR || state == SM_LANDED) {
		return;
	}

	/* Continuous recording already opened the log at boot. */
	if (!IS_ENABLED(CONFIG_DATA_LOGGER_LOG_ONLY_INFLIGHT)) {
		return;
	}

	/* Failure latches flight_recording_failed, which drops the state
	 * machine back to IDLE via log_flight_log_online().  Mid-flight that
	 * safes the charges, which is a real cost -- but it is the same
	 * bargain the arm path already makes, and a vehicle that is armed
	 * without a recording is the outcome that latch exists to prevent.
	 */
	log_begin_flight();
}

void log_flight_telemetry(void)
{
	struct sm_inputs sm_in;
	sm_get_inputs(&sm_in);

	uint64_t ts = k_ticks_to_ns_floor64(k_uptime_ticks());
	struct datapoint kin_dp = {
		.timestamp_ns = ts,
		.type = AURORA_DATA_SM_KINEMATICS,
		.channel_count = 2,
	};
	sensor_value_from_double(&kin_dp.channels[0], sm_in.acceleration);
	sensor_value_from_double(&kin_dp.channels[1], sm_in.accel_vert);
	log_enqueue(&kin_dp);

	struct datapoint pose_dp = {
		.timestamp_ns = ts,
		.type = AURORA_DATA_SM_POSE,
		.channel_count = 2,
	};
	sensor_value_from_double(&pose_dp.channels[0], sm_in.velocity);
	sensor_value_from_double(&pose_dp.channels[1], sm_in.altitude);
	log_enqueue(&pose_dp);

	struct datapoint or_dp = {
		.timestamp_ns = ts,
		.type = AURORA_DATA_ORIENTATION,
		.channel_count = 3,
	};
	sensor_value_from_double(&or_dp.channels[0], sm_in.orientation[0]);
	sensor_value_from_double(&or_dp.channels[1], sm_in.orientation[1]);
	sensor_value_from_double(&or_dp.channels[2], sm_in.orientation[2]);
	log_enqueue(&or_dp);
}

#if DT_HAS_CHOSEN(auxspace_vbat)
/* Battery voltage changes slowly; cap the ADC sample rate independently of
 * the (much faster) state-machine telemetry cadence.
 */
#define LOG_VBAT_PERIOD_MS 500

static const struct device *const vbat_dev = DEVICE_DT_GET(DT_CHOSEN(auxspace_vbat));

void log_vbat_telemetry(void)
{
	static int64_t next_sample_ms;

	int64_t now = k_uptime_get();
	if (now < next_sample_ms) {
		return;
	}
	next_sample_ms = now + LOG_VBAT_PERIOD_MS;

	if (!device_is_ready(vbat_dev)) {
		return;
	}

	struct sensor_value voltage;
	if (sensor_sample_fetch(vbat_dev) != 0 ||
	    sensor_channel_get(vbat_dev, SENSOR_CHAN_VOLTAGE, &voltage) != 0) {
		LOG_WRN("vbat read failed");
		return;
	}

	struct datapoint dp = {
		.timestamp_ns = k_ticks_to_ns_floor64(k_uptime_ticks()),
		.type = AURORA_DATA_VBAT,
		.channel_count = 1,
		.channels = {voltage},
	};
	log_enqueue(&dp);
}
#else
/* No battery-sense node in the devicetree — nothing to log. */
void log_vbat_telemetry(void) {}
#endif /* DT_HAS_CHOSEN(auxspace_vbat) */
#endif

#if defined(CONFIG_AURORA_PAD_LINK)

void update_pad_link_data(void)
{
	struct sm_inputs sm_snap;

	sm_get_inputs(&sm_snap);
	pad_link_publish_sm(sm_get_state(), sm_get_type(), &sm_snap);
}
#endif /* CONFIG_AURORA_PAD_LINK */
```

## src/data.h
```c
/**
 * @file data.h
 * @brief Flight-time logging glue for the sensor board state machine.
 *
 * Copyright (c) 2025-2026 Auxspace e.V.
 * SPDX-License-Identifier: Apache-2.0
 */

#ifndef DATA_H
#define DATA_H

#include <stdbool.h>

#include <aurora/lib/baro.h>
#include <aurora/lib/state/state.h>

#if defined(CONFIG_DATA_LOGGER_BIN)
void log_begin_session(void);
void log_handle_flight_lifecycle(const enum sm_state prev_state, const enum sm_state state);
void log_flight_telemetry(void);
void log_vbat_telemetry(void);

/**
 * @brief Open a flight log for a state restored after a watchdog reset.
 *
 * The recovery path writes the state machine's state directly rather than
 * transitioning into it, so the state machine task never sees the
 * IDLE->ARMED edge that @ref log_handle_flight_lifecycle keys the recorder
 * off.  Without this a recovered flight is armed but records nothing, for
 * its whole duration.
 *
 * Replaying the full lifecycle handler instead is not safe: its LANDED
 * branch schedules a close for a log that was never opened.  This covers
 * only the airborne states, where re-opening the recorder is the right
 * answer.  The binary FS backend appends the remainder of the flight to the
 * file the pre-reset part is already in, so the recovered flight reads back
 * as one stream with a gap rather than as two files.
 *
 * @param state State the machine resumed in.
 */
void log_resume_flight_after_reset(const enum sm_state state);
#else
static inline void log_begin_session(void) {}
static inline void log_handle_flight_lifecycle(const enum sm_state prev_state, const enum sm_state state) {}
static inline void log_flight_telemetry(void) {}
static inline void log_vbat_telemetry(void) {}
static inline void log_resume_flight_after_reset(const enum sm_state state) {}
#endif /* CONFIG_DATA_LOGGER_BIN */

#if defined(CONFIG_AURORA_PAD_LINK)
void update_pad_link_data(void);
#else
static inline void update_pad_link_data(void) {}
#endif /*CONFIG_AURORA_PAD_LINK*/

/**
 * @brief Arming precondition: is flight-time data logging available?
 *
 * Feeds @ref sm_inputs.log_ready so the state machine refuses to leave IDLE
 * for ARMED and drops back from ARMED to IDLE pre-boost when the flight
 * cannot be recorded.  False when the boot-time disk bring-up found the raw
 * flight-log region unusable (with CONFIG_DATA_LOGGER_DISK_AUTO_MKFS), or
 * once opening the flight log at ARM time has failed (latched until
 * reboot).  Builds without the binary logger have nothing to gate on and
 * always report ready.
 */
#if defined(CONFIG_DATA_LOGGER_BIN)
bool log_flight_log_online(void);
#else
static inline bool log_flight_log_online(void) { return true; }
#endif /* CONFIG_DATA_LOGGER_BIN */

/**
 * @brief Arming precondition: is the flight log busy with the last flight?
 *
 * Feeds @ref sm_inputs.log_busy so the state machine holds IDLE (rather than
 * erroring) while the post-flight conversion still owns the recorder.
 */
#if defined(CONFIG_DATA_LOGGER_BIN)
bool log_flight_log_busy(void);
#else
static inline bool log_flight_log_busy(void) { return false; }
#endif /* CONFIG_DATA_LOGGER_BIN */

#endif /* DATA_H */
```

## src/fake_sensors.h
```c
/**
 * @file fake_sensors.h
 * @brief Hardware interface supplied by the simulated sensor backends.
 *
 * The synthetic profile generator (fake_sensors.c) and the recorded-flight
 * playback engine (fake_sensors_replay.c) are alternative implementations of
 * this interface, selected by CONFIG_AURORA_FAKE_SENSORS_SYNTH /
 * CONFIG_AURORA_FAKE_SENSORS_REPLAY.  Exactly one of them is compiled in.
 *
 * They supply samples only.  The schedule they are read on belongs to
 * main.c's sensor thread, which drives them through the same slot table it
 * uses for real hardware, so the thread layout, priorities and pacing of a
 * simulated build match the real one.  The @c dev argument exists solely so
 * these match the fetch signature of imu_poll() / baro_measure(); it is
 * unused and callers pass NULL.
 *
 * Copyright (c) 2025-2026 Auxspace e.V.
 * SPDX-License-Identifier: Apache-2.0
 */

#ifndef FAKE_SENSORS_H_
#define FAKE_SENSORS_H_

#include <zephyr/device.h>

/**
 * @brief Prepare the simulated IMU source.
 *
 * @retval 0 on success.
 * @retval -errno if the backend has no usable sample data.
 */
int fake_imu_init(void);

/**
 * @brief Produce one simulated IMU sample and publish it to the z-bus.
 *
 * @param dev Unused; present to match the real fetch signature.
 *
 * @retval 0 on success.
 * @retval -errno if publishing failed.
 */
int fake_imu_poll(const struct device *dev);

/**
 * @brief Prepare the simulated barometer source.
 *
 * @retval 0 on success.
 * @retval -errno if the backend has no usable sample data.
 */
int fake_baro_init(void);

/**
 * @brief Produce one simulated baro sample and publish it to the z-bus.
 *
 * @param dev Unused; present to match the real fetch signature.
 *
 * @retval 0 on success.
 * @retval -errno if publishing failed.
 */
int fake_baro_measure(const struct device *dev);

/**
 * @brief Notify the automatic launch sequence that attitude calibration is
 *        complete.
 *
 * Called from the state machine thread; only the CONFIG_AURORA_SIM_AUTOTEST
 * autolaunch thread acts on it.
 */
void fake_sensors_on_calibrated(void);

#endif /* FAKE_SENSORS_H_ */
```

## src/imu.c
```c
/*
 * Copyright (c) 2025, Auxspace e.V.
 *
 * SPDX-License-Identifier: Apache-2.0
 */

#include <stdlib.h>
#include <stdio.h>
#include <zephyr/kernel.h>
#include <zephyr/device.h>
#include <zephyr/drivers/sensor.h>

#include <lib/imu.h>

static inline float out_ev(struct sensor_value *val)
{
	return (val->val1 + (float)val->val2 / 1000000);
}

static void fetch_and_display(const struct device *dev)
{
	struct sensor_value x, y, z;
	static int trig_cnt;

	trig_cnt++;

	/* lsm6dso accel */
	sensor_sample_fetch_chan(dev, SENSOR_CHAN_ACCEL_XYZ);
	sensor_channel_get(dev, SENSOR_CHAN_ACCEL_X, &x);
	sensor_channel_get(dev, SENSOR_CHAN_ACCEL_Y, &y);
	sensor_channel_get(dev, SENSOR_CHAN_ACCEL_Z, &z);

	printf("accel x:%f ms/2 y:%f ms/2 z:%f ms/2\n",
			(double)out_ev(&x), (double)out_ev(&y), (double)out_ev(&z));

	/* lsm6dso gyro */
	sensor_sample_fetch_chan(dev, SENSOR_CHAN_GYRO_XYZ);
	sensor_channel_get(dev, SENSOR_CHAN_GYRO_X, &x);
	sensor_channel_get(dev, SENSOR_CHAN_GYRO_Y, &y);
	sensor_channel_get(dev, SENSOR_CHAN_GYRO_Z, &z);

	printf("gyro x:%f rad/s y:%f rad/s z:%f rad/s\n",
			(double)out_ev(&x), (double)out_ev(&y), (double)out_ev(&z));

	printf("trig_cnt:%d\n\n", trig_cnt);
}

int imu_set_sampling_freq(const struct device *dev, float sampling_rate_hz)
{
	int ret = 0;
	struct sensor_value odr_attr;

	/* set accel/gyro sampling frequency */
	odr_attr.val1 = sampling_rate_hz;
	odr_attr.val2 = 0;

	ret = sensor_attr_set(dev, SENSOR_CHAN_ACCEL_XYZ,
			SENSOR_ATTR_SAMPLING_FREQUENCY, &odr_attr);
	if (ret != 0) {
		printf("Cannot set sampling frequency for accelerometer.\n");
		return ret;
	}

	ret = sensor_attr_set(dev, SENSOR_CHAN_GYRO_XYZ,
			SENSOR_ATTR_SAMPLING_FREQUENCY, &odr_attr);
	if (ret != 0) {
		printf("Cannot set sampling frequency for gyro.\n");
		return ret;
	}

	return 0;
}

#if defined(CONFIG_LSM6DSO_TRIGGER)
static void trigger_handler(const struct device *dev,
			    const struct sensor_trigger *trig)
{
	fetch_and_display(dev);
}

static void run_trigger_mode(const struct device *dev)
{
	struct sensor_trigger trig;

	trig.type = SENSOR_TRIG_DATA_READY;
	trig.chan = SENSOR_CHAN_ACCEL_XYZ;

	if (sensor_trigger_set(dev, &trig, trigger_handler) != 0) {
		printf("Could not set sensor type and channel\n");
		return;
	}
}

#else
void imu_poll(const struct device *dev)
{
	fetch_and_display(dev);
	return 0;
}
#endif

int imu_init(const struct device *dev)
{
    float imu_hz;

	if (!device_is_ready(dev)) {
		printk("%s: device not ready.\n", dev->name);
		return -ENODEV;
	}

    imu_hz = strtof(CONFIG_IMU_HZ, NULL);
    if (imu_set_sampling_freq(dev, imu_hz) != 0) {
		return -EIO;
	}

#ifdef CONFIG_LSM6DSO_TRIGGER
	printf("Testing LSM6DSO sensor in trigger mode.\n\n");
	run_trigger_mode(dev);
#endif
	return 0;
}
```

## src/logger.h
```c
#ifndef LOGGER_H
#define LOGGER_H

#include <aurora/lib/baro.h>
#include "aurora/lib/state/simple.h"

#if defined(CONFIG_DATA_LOGGER_BIN)
void log_handle_flight_lifecycle(const enum sm_state prev_state, const enum sm_state state);
void log_flight_telemetry();

#else
static inline void log_handle_flight_lifecycle(const enum sm_state prev_state, const enum sm_state state);
static inline void log_flight_telemetry() {};
#endif

#endif
```

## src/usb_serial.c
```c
#include <zephyr/kernel.h>
#include <zephyr/drivers/uart.h>
#include <zephyr/usb/usb_device.h>
#include <zephyr/sys/printk.h>
#include <zephyr/sys/util.h>

#include <string.h>

#include <lib/usb_serial.h>

LOG_MODULE_REGISTER(usb_serial, CONFIG_SENSOR_BOARD_LOG_LEVEL);

/* Check overlay exists for CDC UART console */ 
BUILD_ASSERT(DT_NODE_HAS_COMPAT(DT_CHOSEN(zephyr_console), zephyr_cdc_acm_uart),
	    "Console device is not ACM CDC UART device");

int init_usb_serial() {
    const struct device *usb_device = DEVICE_DT_GET(DT_CHOSEN(zephyr_console));
    uint32_t dtr = 0;

    if (usb_enable(NULL) != 0) {
        return 1;
    }

    while (!dtr) {
        uart_line_ctrl_get(usb_device, UART_LINE_CTRL_DTR, &dtr);
        k_sleep(K_MSEC(100));
    }

    return 0;
}
```

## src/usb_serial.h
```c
/**
 * @brief Initialize the USB serial console.
 *
 * Function initializes a console device for the USB port.
 *
 * @retval zero on success, negative error code on failure.
 */
int init_usb_serial();
```
